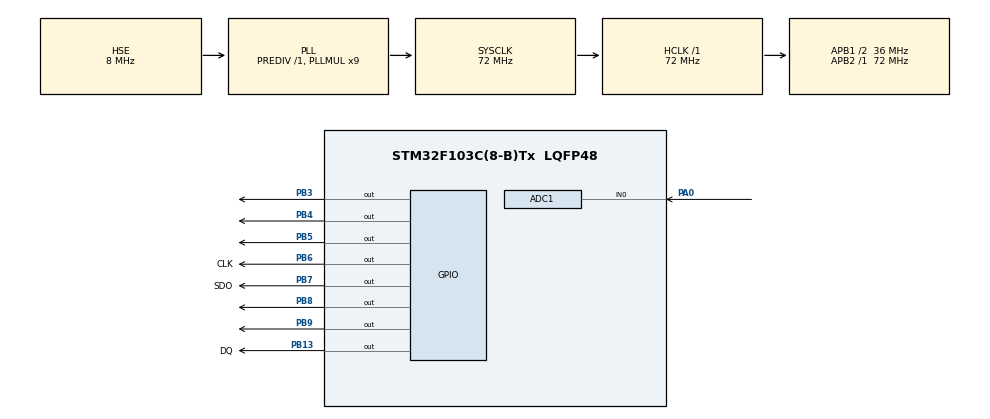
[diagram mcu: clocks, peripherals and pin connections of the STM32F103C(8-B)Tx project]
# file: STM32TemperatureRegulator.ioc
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ADC1.Channel-0\#ChannelRegularConversion=ADC_CHANNEL_0
ADC1.NbrOfConversionFlag=1
ADC1.Rank-0\#ChannelRegularConversion=1
ADC1.SamplingTime-0\#ChannelRegularConversion=ADC_SAMPLETIME_1CYCLE_5
ADC1.master=1
Mcu.Family=STM32F1
Mcu.Name=STM32F103C(8-B)Tx
Mcu.Package=LQFP48
NVIC.ADC1_2_IRQn=true\:0\:0\:false\:false\:true\:true\:true\:true
NVIC.PriorityGroup=NVIC_PRIORITYGROUP_4
NVIC.TIM1_UP_IRQn=true\:0\:0\:false\:false\:true\:true\:true\:true
PA0-WKUP.Signal=ADCx_IN0
PA13.Mode=Serial_Wire
PA13.Signal=SYS_JTMS-SWDIO
PA14.Mode=Serial_Wire
PA14.Signal=SYS_JTCK-SWCLK
PB13.GPIO_Label=DQ
PB13.Signal=GPIO_Output
PB3.Signal=GPIO_Output
PB4.Signal=GPIO_Output
PB5.Signal=GPIO_Output
PB6.GPIO_Label=CLK
PB6.Signal=GPIO_Output
PB7.GPIO_Label=SDO
PB7.Signal=GPIO_Output
PB8.Signal=GPIO_Output
PB9.Signal=GPIO_Output
PD0-OSC_IN.Mode=HSE-External-Oscillator
PD0-OSC_IN.Signal=RCC_OSC_IN
PD1-OSC_OUT.Mode=HSE-External-Oscillator
PD1-OSC_OUT.Signal=RCC_OSC_OUT
ProjectManager.HeapSize=0x200
ProjectManager.StackSize=0x400
ProjectManager.TargetToolchain=STM32CubeIDE
RCC.ADCPresc=RCC_ADCPCLK2_DIV6
RCC.AHBFreq_Value=72000000
RCC.APB1CLKDivider=RCC_HCLK_DIV2
RCC.APB1Freq_Value=36000000
RCC.APB1TimFreq_Value=72000000
RCC.APB2Freq_Value=72000000
RCC.APB2TimFreq_Value=72000000
RCC.HCLKFreq_Value=72000000
RCC.PLLMUL=RCC_PLL_MUL9
RCC.PLLSourceVirtual=RCC_PLLSOURCE_HSE
RCC.SYSCLKFreq_VALUE=72000000
RCC.SYSCLKSource=RCC_SYSCLKSOURCE_PLLCLK
RCC.USBFreq_Value=72000000
SH.ADCx_IN0.0=ADC1_IN0,IN0
TIM1.Period=1
TIM1.Prescaler=35999
TIM2.Period=0xffff-1
TIM2.Prescaler=72-1
VP_TIM1_VS_ClockSourceINT.Mode=Internal
VP_TIM2_VS_ClockSourceINT.Mode=Internal
board=custom

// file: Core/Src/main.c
/* USER CODE BEGIN Header */
/**
  ******************************************************************************
  * @file           : main.c
  * @brief          : Main program body
  ******************************************************************************
  * @attention
  *
  * Copyright (c) 2023 STMicroelectronics.
  * All rights reserved.
  *
  * This software is licensed under terms that can be found in the LICENSE file
  * in the root directory of this software component.
  * If no LICENSE file comes with this software, it is provided AS-IS.
  *
  ******************************************************************************
  */
/* USER CODE END Header */
#include "main.h"

ADC_HandleTypeDef hadc1;

TIM_HandleTypeDef htim1;
TIM_HandleTypeDef htim2;

void SystemClock_Config(void);
static void MX_GPIO_Init(void);
static void MX_TIM1_Init(void);
static void MX_TIM2_Init(void);
static void MX_ADC1_Init(void);
/* USER CODE BEGIN PFP */

void Timer1_Interrupt();

/* USER CODE END PFP */

/* USER CODE BEGIN 0 */

uint16_t Timer1Cnt = 0;
//unsigned char KeyboardDelay = 50;
unsigned char KeyboardReadFlag = 0;
//unsigned char LedBlinkFlag = 0;
//unsigned char RFIDFlag = 0;

void Timer1_Interrupt()
{
	if(Timer1Cnt == 1000)
	{
		KeyboardReadFlag = 1;
		Timer1Cnt = 0;
	}
	++Timer1Cnt;
}
/* USER CODE END 0 */

int main(void)
{

  /* MCU Configuration--------------------------------------------------------*/

  /* Reset of all peripherals, Initializes the Flash interface and the Systick. */
  HAL_Init();

  /* USER CODE BEGIN Init */
  //CppMain(); // init CPP objects
  /* USER CODE END Init */

  /* Configure the system clock */
  SystemClock_Config();

  /* Initialize all configured peripherals */
  MX_GPIO_Init();
  MX_TIM1_Init();
  MX_TIM2_Init();
  MX_ADC1_Init();
  /* USER CODE BEGIN 2 */
  HAL_TIM_Base_Start_IT(&htim1);
  //HAL_GPIO_WritePin(GPIOB, GPIO_PIN_6, GPIO_PIN_SET);
  //HAL_GPIO_WritePin(GPIOB, GPIO_PIN_7, GPIO_PIN_SET);
  /* USER CODE END 2 */

  /* Infinite loop */
  /* USER CODE BEGIN WHILE */

  CppMain();

  while (1)
  {
	  	  // Keyboard polling
	  	  	 /* if(KeyboardReadFlag)
	  	  	  {
	  	  		  //KeyboardProcess();
	  	  		  KeyboardReadFlag = 0;
	  	  	  }*/

    /* USER CODE END WHILE */

  }
}

void SystemClock_Config(void)
{
  RCC_OscInitTypeDef RCC_OscInitStruct = {0};
  RCC_ClkInitTypeDef RCC_ClkInitStruct = {0};
  RCC_PeriphCLKInitTypeDef PeriphClkInit = {0};

  /** Initializes the RCC Oscillators according to the specified parameters
  * in the RCC_OscInitTypeDef structure.
  */
  RCC_OscInitStruct.OscillatorType = RCC_OSCILLATORTYPE_HSE;
  RCC_OscInitStruct.HSEState = RCC_HSE_ON;
  RCC_OscInitStruct.HSEPredivValue = RCC_HSE_PREDIV_DIV1;
  RCC_OscInitStruct.HSIState = RCC_HSI_ON;
  RCC_OscInitStruct.PLL.PLLState = RCC_PLL_ON;
  RCC_OscInitStruct.PLL.PLLSource = RCC_PLLSOURCE_HSE;
  RCC_OscInitStruct.PLL.PLLMUL = RCC_PLL_MUL9;
  if (HAL_RCC_OscConfig(&RCC_OscInitStruct) != HAL_OK)
  {
    Error_Handler();
  }

  /** Initializes the CPU, AHB and APB buses clocks
  */
  RCC_ClkInitStruct.ClockType = RCC_CLOCKTYPE_HCLK|RCC_CLOCKTYPE_SYSCLK
                              |RCC_CLOCKTYPE_PCLK1|RCC_CLOCKTYPE_PCLK2;
  RCC_ClkInitStruct.SYSCLKSource = RCC_SYSCLKSOURCE_PLLCLK;
  RCC_ClkInitStruct.AHBCLKDivider = RCC_SYSCLK_DIV1;
  RCC_ClkInitStruct.APB1CLKDivider = RCC_HCLK_DIV2;
  RCC_ClkInitStruct.APB2CLKDivider = RCC_HCLK_DIV1;

  if (HAL_RCC_ClockConfig(&RCC_ClkInitStruct, FLASH_LATENCY_2) != HAL_OK)
  {
    Error_Handler();
  }
  PeriphClkInit.PeriphClockSelection = RCC_PERIPHCLK_ADC;
  PeriphClkInit.AdcClockSelection = RCC_ADCPCLK2_DIV6;
  if (HAL_RCCEx_PeriphCLKConfig(&PeriphClkInit) != HAL_OK)
  {
    Error_Handler();
  }
}

static void MX_ADC1_Init(void)
{

  ADC_ChannelConfTypeDef sConfig = {0};

  /** Common config
  */
  hadc1.Instance = ADC1;
  hadc1.Init.ScanConvMode = ADC_SCAN_DISABLE;
  hadc1.Init.ContinuousConvMode = DISABLE;
  hadc1.Init.DiscontinuousConvMode = DISABLE;
  hadc1.Init.ExternalTrigConv = ADC_SOFTWARE_START;
  hadc1.Init.DataAlign = ADC_DATAALIGN_RIGHT;
  hadc1.Init.NbrOfConversion = 1;
  if (HAL_ADC_Init(&hadc1) != HAL_OK)
  {
    Error_Handler();
  }

  /** Configure Regular Channel
  */
  sConfig.Channel = ADC_CHANNEL_0;
  sConfig.Rank = ADC_REGULAR_RANK_1;
  sConfig.SamplingTime = ADC_SAMPLETIME_1CYCLE_5;
  if (HAL_ADC_ConfigChannel(&hadc1, &sConfig) != HAL_OK)
  {
    Error_Handler();
  }

}

static void MX_TIM1_Init(void)
{

  TIM_ClockConfigTypeDef sClockSourceConfig = {0};
  TIM_MasterConfigTypeDef sMasterConfig = {0};

  htim1.Instance = TIM1;
  htim1.Init.Prescaler = 35999;
  htim1.Init.CounterMode = TIM_COUNTERMODE_UP;
  htim1.Init.Period = 1;
  htim1.Init.ClockDivision = TIM_CLOCKDIVISION_DIV1;
  htim1.Init.RepetitionCounter = 0;
  htim1.Init.AutoReloadPreload = TIM_AUTORELOAD_PRELOAD_DISABLE;
  if (HAL_TIM_Base_Init(&htim1) != HAL_OK)
  {
    Error_Handler();
  }
  sClockSourceConfig.ClockSource = TIM_CLOCKSOURCE_INTERNAL;
  if (HAL_TIM_ConfigClockSource(&htim1, &sClockSourceConfig) != HAL_OK)
  {
    Error_Handler();
  }
  sMasterConfig.MasterOutputTrigger = TIM_TRGO_RESET;
  sMasterConfig.MasterSlaveMode = TIM_MASTERSLAVEMODE_DISABLE;
  if (HAL_TIMEx_MasterConfigSynchronization(&htim1, &sMasterConfig) != HAL_OK)
  {
    Error_Handler();
  }

}

static void MX_TIM2_Init(void)
{

  TIM_ClockConfigTypeDef sClockSourceConfig = {0};
  TIM_MasterConfigTypeDef sMasterConfig = {0};

  htim2.Instance = TIM2;
  htim2.Init.Prescaler = 72-1;
  htim2.Init.CounterMode = TIM_COUNTERMODE_UP;
  htim2.Init.Period = 0xffff-1;
  htim2.Init.ClockDivision = TIM_CLOCKDIVISION_DIV1;
  htim2.Init.AutoReloadPreload = TIM_AUTORELOAD_PRELOAD_DISABLE;
  if (HAL_TIM_Base_Init(&htim2) != HAL_OK)
  {
    Error_Handler();
  }
  sClockSourceConfig.ClockSource = TIM_CLOCKSOURCE_INTERNAL;
  if (HAL_TIM_ConfigClockSource(&htim2, &sClockSourceConfig) != HAL_OK)
  {
    Error_Handler();
  }
  sMasterConfig.MasterOutputTrigger = TIM_TRGO_RESET;
  sMasterConfig.MasterSlaveMode = TIM_MASTERSLAVEMODE_DISABLE;
  if (HAL_TIMEx_MasterConfigSynchronization(&htim2, &sMasterConfig) != HAL_OK)
  {
    Error_Handler();
  }

}

static void MX_GPIO_Init(void)
{
  GPIO_InitTypeDef GPIO_InitStruct = {0};

  /* GPIO Ports Clock Enable */
  __HAL_RCC_GPIOD_CLK_ENABLE();
  __HAL_RCC_GPIOA_CLK_ENABLE();
  __HAL_RCC_GPIOB_CLK_ENABLE();

  /*Configure GPIO pin Output Level */
  HAL_GPIO_WritePin(GPIOB, DQ_Pin|GPIO_PIN_3|GPIO_PIN_4|GPIO_PIN_5
                          |CLK_Pin|SDO_Pin|GPIO_PIN_8|GPIO_PIN_9, GPIO_PIN_RESET);

  /*Configure GPIO pins : DQ_Pin PB3 PB4 PB5
                           CLK_Pin SDO_Pin PB8 PB9 */
  GPIO_InitStruct.Pin = DQ_Pin|GPIO_PIN_3|GPIO_PIN_4|GPIO_PIN_5
                          |CLK_Pin|SDO_Pin|GPIO_PIN_8|GPIO_PIN_9;
  GPIO_InitStruct.Mode = GPIO_MODE_OUTPUT_PP;
  GPIO_InitStruct.Pull = GPIO_NOPULL;
  GPIO_InitStruct.Speed = GPIO_SPEED_FREQ_LOW;
  HAL_GPIO_Init(GPIOB, &GPIO_InitStruct);

}

void Error_Handler(void)
{
  __disable_irq();
  while (1)
  {
  }
}
